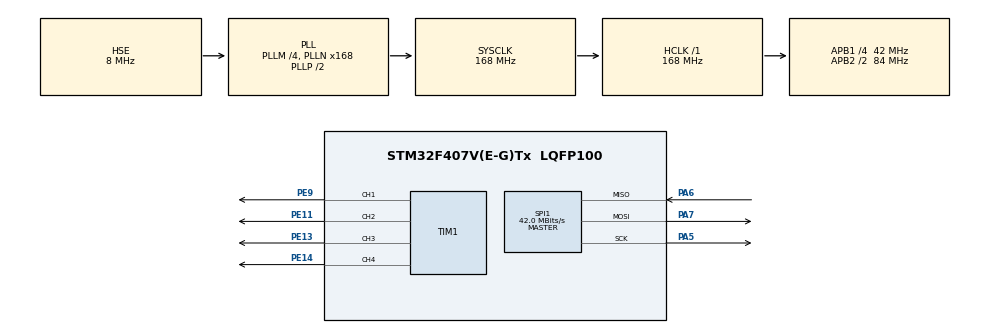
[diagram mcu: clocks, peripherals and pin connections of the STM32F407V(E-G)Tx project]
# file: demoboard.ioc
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FREERTOS.Tasks01=defaultTask,24,128,StartDefaultTask,Default,NULL,Dynamic,NULL,NULL;update_motor_sp,55,128,updMtrSp,Default,NULL,Dynamic,NULL,NULL
FREERTOS.configUSE_NEWLIB_REENTRANT=1
Mcu.Family=STM32F4
Mcu.Name=STM32F407V(E-G)Tx
Mcu.Package=LQFP100
NVIC.PriorityGroup=NVIC_PRIORITYGROUP_4
NVIC.TIM6_DAC_IRQn=true\:15\:0\:false\:false\:true\:false\:false\:true\:true
NVIC.TimeBase=TIM6_DAC_IRQn
NVIC.TimeBaseIP=TIM6
PA13.Mode=Serial_Wire
PA13.Signal=SYS_JTMS-SWDIO
PA14.Mode=Serial_Wire
PA14.Signal=SYS_JTCK-SWCLK
PA5.Mode=Full_Duplex_Master
PA5.Signal=SPI1_SCK
PA6.Mode=Full_Duplex_Master
PA6.Signal=SPI1_MISO
PA7.Mode=Full_Duplex_Master
PA7.Signal=SPI1_MOSI
PE11.Signal=S_TIM1_CH2
PE13.Signal=S_TIM1_CH3
PE14.Signal=S_TIM1_CH4
PE9.Signal=S_TIM1_CH1
PH0-OSC_IN.Mode=HSE-External-Oscillator
PH0-OSC_IN.Signal=RCC_OSC_IN
PH1-OSC_OUT.Mode=HSE-External-Oscillator
PH1-OSC_OUT.Signal=RCC_OSC_OUT
ProjectManager.HeapSize=0x200
ProjectManager.StackSize=0x400
ProjectManager.TargetToolchain=STM32CubeIDE
RCC.48MHZClocksFreq_Value=48000000
RCC.AHBFreq_Value=168000000
RCC.APB1CLKDivider=RCC_HCLK_DIV4
RCC.APB1Freq_Value=42000000
RCC.APB1TimFreq_Value=84000000
RCC.APB2CLKDivider=RCC_HCLK_DIV2
RCC.APB2Freq_Value=84000000
RCC.APB2TimFreq_Value=168000000
RCC.CortexFreq_Value=168000000
RCC.HCLKFreq_Value=168000000
RCC.HSE_VALUE=8000000
RCC.HSI_VALUE=16000000
RCC.LSE_VALUE=32768
RCC.PLLM=4
RCC.PLLN=168
RCC.PLLQ=7
RCC.PLLSourceVirtual=RCC_PLLSOURCE_HSE
RCC.SYSCLKFreq_VALUE=168000000
RCC.SYSCLKSource=RCC_SYSCLKSOURCE_PLLCLK
RCC.VCOOutputFreq_Value=336000000
SH.S_TIM1_CH1.0=TIM1_CH1,Output Compare1 CH1
SH.S_TIM1_CH2.0=TIM1_CH2,Output Compare2 CH2
SH.S_TIM1_CH3.0=TIM1_CH3,Output Compare3 CH3
SH.S_TIM1_CH4.0=TIM1_CH4,Output Compare4 CH4
SPI1.CalculateBaudRate=42.0 MBits/s
SPI1.Direction=SPI_DIRECTION_2LINES
SPI1.Mode=SPI_MODE_MASTER
SPI1.VirtualType=VM_MASTER
TIM1.Channel-Output\ Compare1\ CH1=TIM_CHANNEL_1
TIM1.Channel-Output\ Compare2\ CH2=TIM_CHANNEL_2
TIM1.Channel-Output\ Compare3\ CH3=TIM_CHANNEL_3
TIM1.Channel-Output\ Compare4\ CH4=TIM_CHANNEL_4
VP_FREERTOS_VS_CMSIS_V2.Mode=CMSIS_V2
VP_SYS_VS_tim6.Mode=TIM6
VP_TIM1_VS_ClockSourceINT.Mode=Internal
board=custom

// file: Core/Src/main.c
/* USER CODE BEGIN Header */
/**
  ******************************************************************************
  * @file           : main.c
  * @brief          : Main program body
  ******************************************************************************
  * @attention
  *
  * Copyright (c) 2022 STMicroelectronics.
  * All rights reserved.
  *
  * This software is licensed under terms that can be found in the LICENSE file
  * in the root directory of this software component.
  * If no LICENSE file comes with this software, it is provided AS-IS.
  *
  ******************************************************************************
  */
/* USER CODE END Header */
#include "main.h"
#include "cmsis_os.h"
#include "spi.h"
#include "tim.h"
#include "gpio.h"
#include "spi.h"

void SystemClock_Config(void);
void MX_FREERTOS_Init(void);

int main(void)
{

  /* MCU Configuration--------------------------------------------------------*/

  /* Reset of all peripherals, Initializes the Flash interface and the Systick. */
  HAL_Init();

  /* Configure the system clock */
  SystemClock_Config();

  /* Initialize all configured peripherals */
  MX_GPIO_Init();
  MX_TIM1_Init();
  MX_SPI1_Init();

  /* Init scheduler */
  osKernelInitialize();  /* Call init function for freertos objects (in freertos.c) */
  MX_FREERTOS_Init();

  /* Start scheduler */
  osKernelStart();

  /* We should never get here as control is now taken by the scheduler */
  /* Infinite loop */
  while (1)
  {

  }
}

void SystemClock_Config(void)
{
  RCC_OscInitTypeDef RCC_OscInitStruct = {0};
  RCC_ClkInitTypeDef RCC_ClkInitStruct = {0};

  /** Configure the main internal regulator output voltage
  */
  __HAL_RCC_PWR_CLK_ENABLE();
  __HAL_PWR_VOLTAGESCALING_CONFIG(PWR_REGULATOR_VOLTAGE_SCALE1);

  /** Initializes the RCC Oscillators according to the specified parameters
  * in the RCC_OscInitTypeDef structure.
  */
  RCC_OscInitStruct.OscillatorType = RCC_OSCILLATORTYPE_HSE;
  RCC_OscInitStruct.HSEState = RCC_HSE_ON;
  RCC_OscInitStruct.PLL.PLLState = RCC_PLL_ON;
  RCC_OscInitStruct.PLL.PLLSource = RCC_PLLSOURCE_HSE;
  RCC_OscInitStruct.PLL.PLLM = 4;
  RCC_OscInitStruct.PLL.PLLN = 168;
  RCC_OscInitStruct.PLL.PLLP = RCC_PLLP_DIV2;
  RCC_OscInitStruct.PLL.PLLQ = 7;
  if (HAL_RCC_OscConfig(&RCC_OscInitStruct) != HAL_OK)
  {
    Error_Handler();
  }

  /** Initializes the CPU, AHB and APB buses clocks
  */
  RCC_ClkInitStruct.ClockType = RCC_CLOCKTYPE_HCLK|RCC_CLOCKTYPE_SYSCLK
                              |RCC_CLOCKTYPE_PCLK1|RCC_CLOCKTYPE_PCLK2;
  RCC_ClkInitStruct.SYSCLKSource = RCC_SYSCLKSOURCE_PLLCLK;
  RCC_ClkInitStruct.AHBCLKDivider = RCC_SYSCLK_DIV1;
  RCC_ClkInitStruct.APB1CLKDivider = RCC_HCLK_DIV4;
  RCC_ClkInitStruct.APB2CLKDivider = RCC_HCLK_DIV2;

  if (HAL_RCC_ClockConfig(&RCC_ClkInitStruct, FLASH_LATENCY_5) != HAL_OK)
  {
    Error_Handler();
  }
}

void HAL_TIM_PeriodElapsedCallback(TIM_HandleTypeDef *htim)
{
  if (htim->Instance == TIM6) {
    HAL_IncTick();
  }
}

void Error_Handler(void)
{
  __disable_irq();
  while (1)
  {
  }
}

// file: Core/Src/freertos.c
/* USER CODE BEGIN Header */
/**
  ******************************************************************************
  * File Name          : freertos.c
  * Description        : Code for freertos applications
  ******************************************************************************
  * @attention
  *
  * Copyright (c) 2022 STMicroelectronics.
  * All rights reserved.
  *
  * This software is licensed under terms that can be found in the LICENSE file
  * in the root directory of this software component.
  * If no LICENSE file comes with this software, it is provided AS-IS.
  *
  ******************************************************************************
  */
/* USER CODE END Header */

#include "FreeRTOS.h"
#include "task.h"
#include "main.h"
#include "cmsis_os.h"

/* Definitions for defaultTask */
osThreadId_t defaultTaskHandle;
const osThreadAttr_t defaultTask_attributes = {
  .name = "defaultTask",
  .stack_size = 128 * 4,
  .priority = (osPriority_t) osPriorityNormal,
};
/* Definitions for update_motor_sp */
osThreadId_t update_motor_spHandle;
const osThreadAttr_t update_motor_sp_attributes = {
  .name = "update_motor_sp",
  .stack_size = 128 * 4,
  .priority = (osPriority_t) osPriorityRealtime7,
};

void StartDefaultTask(void *argument);
void updMtrSp(void *argument);

void MX_FREERTOS_Init(void); /* (MISRA C 2004 rule 8.1) */

void MX_FREERTOS_Init(void) {

  /* Create the thread(s) */
  /* creation of defaultTask */
  defaultTaskHandle = osThreadNew(StartDefaultTask, NULL, &defaultTask_attributes);

  /* creation of update_motor_sp */
  update_motor_spHandle = osThreadNew(updMtrSp, NULL, &update_motor_sp_attributes);

}

void StartDefaultTask(void *argument)
{
  for(;;)
  {
    osDelay(1);
  }
}

void updMtrSp(void *argument)
{
  /* USER CODE BEGIN updMtrSp */
  /* Infinite loop */
  for(;;)
  {
	osDelay(2);
    osDelay(1);
  }
  /* USER CODE END updMtrSp */
}
